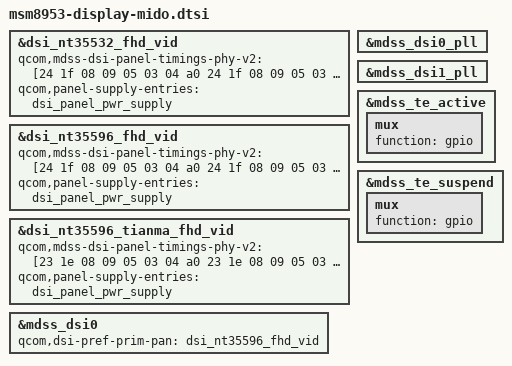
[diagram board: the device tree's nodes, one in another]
/*
 * Copyright (c) 2017, The Linux Foundation. All rights reserved.
 *
 * This program is free software; you can redistribute it and/or modify
 * it under the terms of the GNU General Public License version 2 and
 * only version 2 as published by the Free Software Foundation.
 *
 * This program is distributed in the hope that it will be useful,
 * but WITHOUT ANY WARRANTY; without even the implied warranty of
 * MERCHANTABILITY or FITNESS FOR A PARTICULAR PURPOSE.  See the
 * GNU General Public License for more details.
 */

#include "dsi-panel-nt35532-fhd-video.dtsi"
#include "dsi-panel-nt35596-fhd-video.dtsi"
#include "dsi-panel-nt35596-tianma-fhd-video.dtsi"

&dsi_nt35532_fhd_vid {
        qcom,mdss-dsi-panel-timings-phy-v2 = [24 1f 08 09 05 03 04 a0
                24 1f 08 09 05 03 04 a0
                24 1f 08 09 05 03 04 a0
                24 1f 08 09 05 03 04 a0
                24 1b 08 09 05 03 04 a0];
        qcom,panel-supply-entries = <&dsi_panel_pwr_supply>;
};

&dsi_nt35596_fhd_vid {
        qcom,mdss-dsi-panel-timings-phy-v2 = [24 1f 08 09 05 03 04 a0
                24 1f 08 09 05 03 04 a0
                24 1f 08 09 05 03 04 a0
                24 1f 08 09 05 03 04 a0
                24 1b 08 08 05 03 04 a0];
        qcom,panel-supply-entries = <&dsi_panel_pwr_supply>;
};

&dsi_nt35596_tianma_fhd_vid {
        qcom,mdss-dsi-panel-timings-phy-v2 = [23 1e 08 09 05 03 04 a0
                23 1e 08 09 05 03 04 a0
                23 1e 08 09 05 03 04 a0
                23 1e 08 09 05 03 04 a0
                23 1a 08 09 05 03 04 a0];
        qcom,panel-supply-entries = <&dsi_panel_pwr_supply>;
};

&mdss_dsi0 {
        qcom,dsi-pref-prim-pan = <&dsi_nt35596_fhd_vid>;
};

&mdss_dsi0_pll {
        /delete-property/ qcom,dsi-pll-ssc-en;
        /delete-property/ qcom,dsi-pll-ssc-mode;
};

&mdss_dsi1_pll {
        /delete-property/ qcom,dsi-pll-ssc-en;
        /delete-property/ qcom,dsi-pll-ssc-mode;
};

&mdss_te_active {
        mux {
                function = "gpio";
        };
};

&mdss_te_suspend {
        mux {
                function = "gpio";
        };
};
